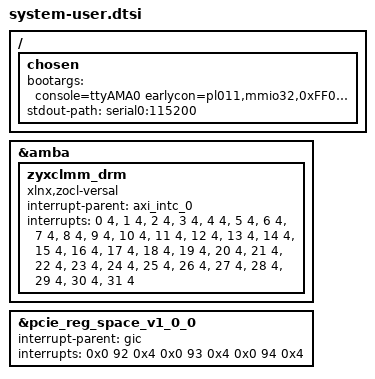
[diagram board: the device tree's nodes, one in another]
/include/ "system-conf.dtsi"
/include/ "pcie.dtsi"
/ {
	chosen {
		 bootargs = "console=ttyAMA0 earlycon=pl011,mmio32,0xFF000000,115200n8 clk_ignore_unused root=/dev/mmcblk0p2 rw rootwait";
		stdout-path = "serial0:115200";
	};
};
&amba {
	zyxclmm_drm {
		compatible = "xlnx,zocl-versal";
		status = "okay";
		interrupt-parent = <&axi_intc_0>;
		interrupts = <0  4>, <1  4>, <2  4>, <3  4>,
		     <4  4>, <5  4>, <6  4>, <7  4>,
		     <8  4>, <9  4>, <10 4>, <11 4>,
		     <12 4>, <13 4>, <14 4>, <15 4>,
		     <16 4>, <17 4>, <18 4>, <19 4>,
		     <20 4>, <21 4>, <22 4>, <23 4>,
		     <24 4>, <25 4>, <26 4>, <27 4>,
		     <28 4>, <29 4>, <30 4>, <31 4>;
	};
};
&pcie_reg_space_v1_0_0 {
    interrupt-parent = <&gic>;
    interrupts = <0x0 92 0x4 0x0 93 0x4 0x0 94 0x4 >;
    interrupt-names = "read", "write", "close";
};
#include "pl-custom.dtsi"
